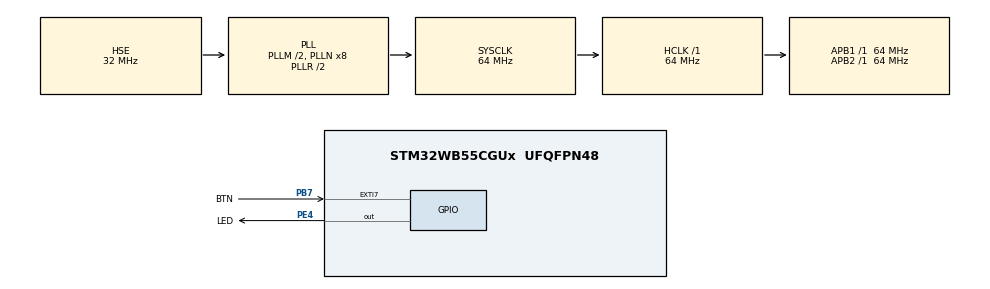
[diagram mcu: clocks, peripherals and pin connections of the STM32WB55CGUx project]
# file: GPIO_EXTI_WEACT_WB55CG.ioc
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Mcu.Family=STM32WB
Mcu.Name=STM32WB55CGUx
Mcu.Package=UFQFPN48
NVIC.EXTI9_5_IRQn=true\:0\:0\:false\:false\:true\:true\:true\:true
NVIC.PriorityGroup=NVIC_PRIORITYGROUP_4
OSC_IN.Mode=HSE-External-Oscillator
OSC_IN.Signal=RCC_OSC_IN
OSC_OUT.Mode=HSE-External-Oscillator
OSC_OUT.Signal=RCC_OSC_OUT
PB7.GPIO_Label=BTN
PB7.GPIO_PuPd=GPIO_PULLUP
PB7.Signal=GPXTI7
PC14-OSC32_IN.Mode=LSE-External-Oscillator
PC14-OSC32_IN.Signal=RCC_OSC32_IN
PC15-OSC32_OUT.Mode=LSE-External-Oscillator
PC15-OSC32_OUT.Signal=RCC_OSC32_OUT
PE4.GPIO_Label=LED
PE4.Signal=GPIO_Output
ProjectManager.HeapSize=0x200
ProjectManager.StackSize=0x400
ProjectManager.TargetToolchain=STM32CubeIDE
RCC.ADCFreq_Value=64000000
RCC.AHB2CLKDivider=RCC_SYSCLK_DIV2
RCC.AHBFreq_Value=64000000
RCC.APB1Freq_Value=64000000
RCC.APB1TimFreq_Value=64000000
RCC.APB2Freq_Value=64000000
RCC.APB2TimFreq_Value=64000000
RCC.APB3Freq_Value=16000000
RCC.Cortex2_Div=SYSTICK_CLKSOURCE_HCLK_DIV8
RCC.CortexFreq_Value=64000000
RCC.HCLKFreq_Value=64000000
RCC.HSE_VALUE=32000000
RCC.HSI48_VALUE=48000000
RCC.HSI_VALUE=16000000
RCC.PLLM=RCC_PLLM_DIV2
RCC.PLLSourceVirtual=RCC_PLLSOURCE_HSE
RCC.RTCClockSelection=RCC_RTCCLKSOURCE_LSE
RCC.SYSCLKFreq_VALUE=64000000
RCC.SYSCLKSource=RCC_SYSCLKSOURCE_PLLCLK
RCC.USBFreq_Value=64000000
RCC.VCOOutputFreq_Value=128000000
VP_MEMORYMAP_VS_MEMORYMAP.Mode=CurAppReg
VP_RTC_VS_RTC_Activate.Mode=RTC_Enabled
board=custom

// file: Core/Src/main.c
/* USER CODE BEGIN Header */
/**
  ******************************************************************************
  * @file           : main.c
  * @brief          : Main program body
  ******************************************************************************
  * @attention
  *
  * Copyright (c) 2026 STMicroelectronics.
  * All rights reserved.
  *
  * This software is licensed under terms that can be found in the LICENSE file
  * in the root directory of this software component.
  * If no LICENSE file comes with this software, it is provided AS-IS.
  *
  ******************************************************************************
  */
/* USER CODE END Header */
#include "main.h"

RTC_HandleTypeDef hrtc;

/* USER CODE BEGIN PV */
volatile uint32_t led_delay = 1000; // Default awal 1 detik (1000 ms)
uint32_t previous_tick = 0;
/* USER CODE END PV */

void SystemClock_Config(void);
void PeriphCommonClock_Config(void);
static void MX_GPIO_Init(void);
static void MX_RTC_Init(void);
/* USER CODE BEGIN PFP */
void HAL_GPIO_EXTI_Callback(uint16_t GPIO_Pin);
/* USER CODE END PFP */

int main(void)
{

  /* MCU Configuration--------------------------------------------------------*/

  /* Reset of all peripherals, Initializes the Flash interface and the Systick. */
  HAL_Init();

  /* Configure the system clock */
  SystemClock_Config();

  /* Configure the peripherals common clocks */
  PeriphCommonClock_Config();

  /* Initialize all configured peripherals */
  MX_GPIO_Init();
  MX_RTC_Init();

  /* Infinite loop */
  /* USER CODE BEGIN WHILE */
  while (1)
  {
		// Menggunakan non-blocking delay agar perubahan led_delay langsung terasa instant
		if (HAL_GetTick() - previous_tick >= led_delay)
		{
		  previous_tick = HAL_GetTick();
		  HAL_GPIO_TogglePin(GPIOE, GPIO_PIN_4); // Toggle LED di PE4
		}
    /* USER CODE END WHILE */

  }
}

void SystemClock_Config(void)
{
  RCC_OscInitTypeDef RCC_OscInitStruct = {0};
  RCC_ClkInitTypeDef RCC_ClkInitStruct = {0};

  /** Configure LSE Drive Capability
  */
  HAL_PWR_EnableBkUpAccess();
  __HAL_RCC_LSEDRIVE_CONFIG(RCC_LSEDRIVE_MEDIUMHIGH);

  /** Configure the main internal regulator output voltage
  */
  __HAL_PWR_VOLTAGESCALING_CONFIG(PWR_REGULATOR_VOLTAGE_SCALE1);

  /** Initializes the RCC Oscillators according to the specified parameters
  * in the RCC_OscInitTypeDef structure.
  */
  RCC_OscInitStruct.OscillatorType = RCC_OSCILLATORTYPE_HSI|RCC_OSCILLATORTYPE_HSE
                              |RCC_OSCILLATORTYPE_LSE;
  RCC_OscInitStruct.HSEState = RCC_HSE_ON;
  RCC_OscInitStruct.LSEState = RCC_LSE_ON;
  RCC_OscInitStruct.HSIState = RCC_HSI_ON;
  RCC_OscInitStruct.HSICalibrationValue = RCC_HSICALIBRATION_DEFAULT;
  RCC_OscInitStruct.PLL.PLLState = RCC_PLL_ON;
  RCC_OscInitStruct.PLL.PLLSource = RCC_PLLSOURCE_HSE;
  RCC_OscInitStruct.PLL.PLLM = RCC_PLLM_DIV2;
  RCC_OscInitStruct.PLL.PLLN = 8;
  RCC_OscInitStruct.PLL.PLLP = RCC_PLLP_DIV2;
  RCC_OscInitStruct.PLL.PLLR = RCC_PLLR_DIV2;
  RCC_OscInitStruct.PLL.PLLQ = RCC_PLLQ_DIV2;
  if (HAL_RCC_OscConfig(&RCC_OscInitStruct) != HAL_OK)
  {
    Error_Handler();
  }

  /** Configure the SYSCLKSource, HCLK, PCLK1 and PCLK2 clocks dividers
  */
  RCC_ClkInitStruct.ClockType = RCC_CLOCKTYPE_HCLK4|RCC_CLOCKTYPE_HCLK2
                              |RCC_CLOCKTYPE_HCLK|RCC_CLOCKTYPE_SYSCLK
                              |RCC_CLOCKTYPE_PCLK1|RCC_CLOCKTYPE_PCLK2;
  RCC_ClkInitStruct.SYSCLKSource = RCC_SYSCLKSOURCE_PLLCLK;
  RCC_ClkInitStruct.AHBCLKDivider = RCC_SYSCLK_DIV1;
  RCC_ClkInitStruct.APB1CLKDivider = RCC_HCLK_DIV1;
  RCC_ClkInitStruct.APB2CLKDivider = RCC_HCLK_DIV1;
  RCC_ClkInitStruct.AHBCLK2Divider = RCC_SYSCLK_DIV2;
  RCC_ClkInitStruct.AHBCLK4Divider = RCC_SYSCLK_DIV1;

  if (HAL_RCC_ClockConfig(&RCC_ClkInitStruct, FLASH_LATENCY_3) != HAL_OK)
  {
    Error_Handler();
  }
}

void PeriphCommonClock_Config(void)
{
  RCC_PeriphCLKInitTypeDef PeriphClkInitStruct = {0};

  /** Initializes the peripherals clock
  */
  PeriphClkInitStruct.PeriphClockSelection = RCC_PERIPHCLK_SMPS;
  PeriphClkInitStruct.SmpsClockSelection = RCC_SMPSCLKSOURCE_HSI;
  PeriphClkInitStruct.SmpsDivSelection = RCC_SMPSCLKDIV_RANGE1;

  if (HAL_RCCEx_PeriphCLKConfig(&PeriphClkInitStruct) != HAL_OK)
  {
    Error_Handler();
  }
}

static void MX_RTC_Init(void)
{

  /** Initialize RTC Only
  */
  hrtc.Instance = RTC;
  hrtc.Init.HourFormat = RTC_HOURFORMAT_24;
  hrtc.Init.AsynchPrediv = 127;
  hrtc.Init.SynchPrediv = 255;
  hrtc.Init.OutPut = RTC_OUTPUT_DISABLE;
  hrtc.Init.OutPutPolarity = RTC_OUTPUT_POLARITY_HIGH;
  hrtc.Init.OutPutType = RTC_OUTPUT_TYPE_OPENDRAIN;
  hrtc.Init.OutPutRemap = RTC_OUTPUT_REMAP_NONE;
  if (HAL_RTC_Init(&hrtc) != HAL_OK)
  {
    Error_Handler();
  }

}

static void MX_GPIO_Init(void)
{
  GPIO_InitTypeDef GPIO_InitStruct = {0};

  /* GPIO Ports Clock Enable */
  __HAL_RCC_GPIOC_CLK_ENABLE();
  __HAL_RCC_GPIOE_CLK_ENABLE();
  __HAL_RCC_GPIOB_CLK_ENABLE();

  /*Configure GPIO pin Output Level */
  HAL_GPIO_WritePin(LED_GPIO_Port, LED_Pin, GPIO_PIN_RESET);

  /*Configure GPIO pin : LED_Pin */
  GPIO_InitStruct.Pin = LED_Pin;
  GPIO_InitStruct.Mode = GPIO_MODE_OUTPUT_PP;
  GPIO_InitStruct.Pull = GPIO_NOPULL;
  GPIO_InitStruct.Speed = GPIO_SPEED_FREQ_LOW;
  HAL_GPIO_Init(LED_GPIO_Port, &GPIO_InitStruct);

  /*Configure GPIO pin : BTN_Pin */
  GPIO_InitStruct.Pin = BTN_Pin;
  GPIO_InitStruct.Mode = GPIO_MODE_IT_RISING;
  GPIO_InitStruct.Pull = GPIO_PULLUP;
  HAL_GPIO_Init(BTN_GPIO_Port, &GPIO_InitStruct);

  /* EXTI interrupt init*/
  HAL_NVIC_SetPriority(EXTI9_5_IRQn, 0, 0);
  HAL_NVIC_EnableIRQ(EXTI9_5_IRQn);

}

/* USER CODE BEGIN 4 */
void HAL_GPIO_EXTI_Callback(uint16_t GPIO_Pin)
{
  // Pastikan interupsi berasal dari pin PB7
  if (GPIO_Pin == GPIO_PIN_7)
  {
    // Debouncing sederhana berbasis software agar tidak memicu interupsi ganda saat ditekan
    static uint32_t last_exti_tick = 0;
    if (HAL_GetTick() - last_exti_tick > 200)
    {
      if (led_delay > 100)
      {
        led_delay -= 100; // Kurangi delay sebesar 100ms
      }
      else
      {
        led_delay = 1000; // Jika sudah mencapai batas (100ms), reset kembali ke 1 detik
      }
      last_exti_tick = HAL_GetTick();
    }
  }
}
/* USER CODE END 4 */

void Error_Handler(void)
{
  __disable_irq();
  while (1)
  {
  }
}
